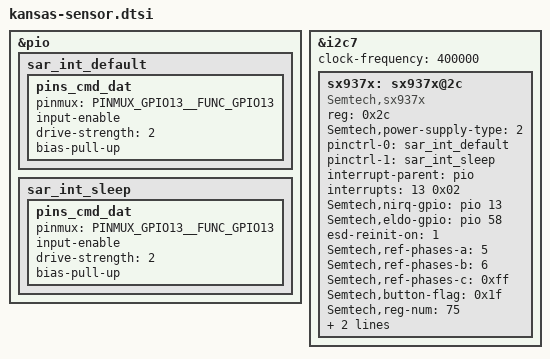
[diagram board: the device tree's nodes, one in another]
/*
 * Copyright (c) 2019 MediaTek Inc.
 *
 * This program is free software; you can redistribute it and/or modify
 * it under the terms of the GNU General Public License version 2 as
 * published by the Free Software Foundation.
 *
 * This program is distributed in the hope that it will be useful,
 * but WITHOUT ANY WARRANTY; without even the implied warranty of
 * MERCHANTABILITY or FITNESS FOR A PARTICULAR PURPOSE.  See the
 * GNU General Public License for more details.
 */

&pio {
	sar_int_default: sar_int_default {
		pins_cmd_dat {
			pinmux = <PINMUX_GPIO13__FUNC_GPIO13>;
			input-enable;
			drive-strength = <2>;
			bias-pull-up;
		};
	};

	sar_int_sleep: sar_int_sleep {
		pins_cmd_dat {
			pinmux = <PINMUX_GPIO13__FUNC_GPIO13>;
			input-enable;
			drive-strength = <2>;
			bias-pull-up;
		};
	};
};


&i2c7 {
	status = "okay";
	clock-frequency = <400000>;
	sx937x:sx937x@2c {
		compatible = "Semtech,sx937x";
		reg = <0x2c>;
		Semtech,power-supply-type = <2>;
		pinctrl-names = "default","sleep";
		pinctrl-0 = <&sar_int_default>;
		pinctrl-1 = <&sar_int_sleep>;
		interrupt-parent = <&pio>;
		interrupts = <13 0x02>;
		interrupt-names = "sx937x_irq";
		Semtech,nirq-gpio = <&pio 13 0x02>;
		//cap_vdd-supply = <&mt6377_vio18>;
		Semtech,eldo-gpio = <&pio 58 0x00>;
                esd-reinit-on = <1>;
		/*use PH4/5/6 as the reference sensor
		set it to 0xff if the ref-phases-x is not used*/
		Semtech,ref-phases-a = <5>;
		Semtech,ref-phases-b = <6>;
		Semtech,ref-phases-c = <0xff>;
		Semtech,button-flag = <0x1f>;
		Semtech,reg-num = <75>;
		Semtech,reg-init = <
				0x8024 0x7F00
				0x4004 0x78
				0x8008 0x0
				0x8020 0x32
				0x8028 0x40E
				0x8034 0x41E
				0x8040 0x41E
				0x804C 0x40E
				0x8058 0x40E
				0x8064 0x41E
				0x8070 0x41E
				0x807C 0x41E
				0x8030 0xFFF9FD
				0x803C 0xBFF9FF
				0x8048 0xFFF97F
				0x8054 0xFFD9FF
				0x8060 0xFEF9FF
				0x806C 0xFFF9EF
				0x8078 0xF7F9FF
				0x8084 0x924924
				0x802C 0x0
				0x8038 0x0
				0x8044 0x0
				0x8050 0x0
				0x805C 0x0
				0x8068 0x0
				0x8074 0x0
				0x8080 0x0
				0x8098 0x6E5A
				0x80B8 0x4737
				0x80D8 0x5447
				0x80F8 0x6E64
				0x8118 0x5A4E
				0x8138 0xFF
				0x8158 0xFF
				0x8178 0xFF
				0x80A0 0x1
				0x80C0 0x2
				0x80E0 0x1
				0x8100 0x0
				0x8120 0x2
				0x8140 0x0
				0x8160 0x0
				0x8180 0x0
				0x8188 0x8000015
				0x818C 0x8000016
				0x8190 0x0
				0x8194 0x0
				0x8090 0x7F815000
				0x80B0 0x7F815000
				0x80D0 0x7F815000
				0x80F0 0x7F815000
				0x8110 0x7F815000
				0x8130 0x54AC5300
				0x8150 0x54AC5300
				0x8170 0x54AC5300
				0x8088 0x400000
				0x80A8 0x400000
				0x80C8 0x400000
				0x80E8 0x400000
				0x8108 0x400000
				0x8128 0x400000
				0x8148 0x400000
				0x8168 0x300000
				0x808C 0x60200031
				0x80AC 0x60200031
				0x80CC 0x60200031
				0x80EC 0x60200031
				0x810C 0x60200031
				0x812C 0x60200031
				0x814C 0x60200031
				0x816C 0x60200031
				0x8024 0x7F7F
				0x4008 0x08
				0x4280 0x0E
		>;

		status = "okay";
	};
};
